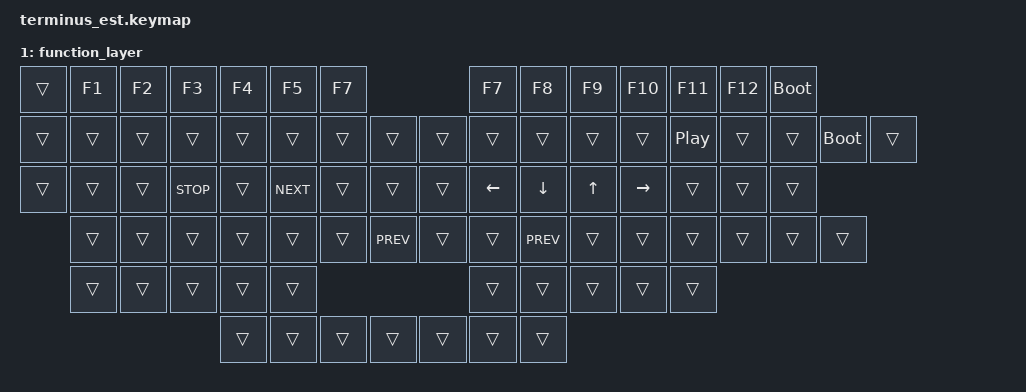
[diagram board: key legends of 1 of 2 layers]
/*
 * Copyright (c) 2024 The ZMK Contributors
 *
 * SPDX-License-Identifier: MIT
 */

#include <behaviors.dtsi>
#include <dt-bindings/zmk/keys.h>
#include <dt-bindings/zmk/bt.h>

/ {
    keymap {
        compatible = "zmk,keymap";

        default_layer {
// -----------------------------------------------------------------------------------------
// |  `  |  1  |  2  |  3  |  4  |  5  |  6  |                     |  7  |  8  |  9  |  0  |  -  |  +  | BKSP |
// | TAB | TAB |  Q  |  W  |  E  |  R  |  T  |  ESC |       | ESC |  Y  |  U  |  I  |  O  |  P  |  {  |  }  | BKSP |
// | CTRL| CTRL|  A  |  S  |  D  |  F  |  G  |  ALT |       | ALT |  H  |  J  |  K  |  L  |  ;  |  '  |  \  |
//       | SHFT| SHFT|  Z  |  X  |  C  |  V  |  B  |  CMD |       | CMD |  B  |  N  |  M  |  ,  |  .  |  /  | ENT |
//       | SHFT| SHFT|     | SPC | SPC | SPC |                     | SPC | SPC | SPC | ENT | ENT |
//                           | SPC | SPC | SPC |  FN  |       | SPC | SPC | SPC |
            bindings = <
   &kp GRAVE  &kp N1   &kp N2   &kp N3   &kp N4   &kp N5   &kp N6                         &kp N7   &kp N8    &kp N9    &kp N0   &kp MINUS &kp PLUS  &kp BSPC
   &kp TAB    &kp TAB  &kp Q    &kp W    &kp E    &kp R    &kp T    &kp ESC      &kp ESC   &kp Y    &kp U     &kp I     &kp O    &kp P     &kp LBRC  &kp RBRC  &kp BSPC
   &kp LCTRL  &kp LCTRL &kp A   &kp S    &kp D    &kp F    &kp G    &kp LALT     &kp LALT  &kp H    &kp J     &kp K     &kp L    &kp SEMI  &kp SQT   &kp BSLH
              &kp LSHFT &kp LSHFT &kp Z  &kp X    &kp C    &kp V    &kp B        &kp LGUI  &kp LGUI &kp B     &kp N     &kp M    &kp COMMA &kp DOT   &kp FSLH  &kp RET
              &kp LSHFT &kp LSHFT        &kp SPACE &kp SPACE &kp SPACE                     &kp SPACE &kp SPACE &kp SPACE &kp RET   &kp RET
                                         &kp SPACE &kp SPACE &kp SPACE &mo 1      &kp SPACE &kp SPACE &kp SPACE
            >;
        };

        function_layer {
// -----------------------------------------------------------------------------------------
// |     | F1  | F2  | F3  | F4  | F5  | F7  |                     | F7  | F8  | F9  | F10 | F11 | F12 | BOOT |
// |     |     |     |     |     |     |     |     |       |     |     |     |     |     | PLAY|     |     | BOOT |
// |     |     |     | STOP|     | NEXT|     |     |       |     | ← | ↓ | ↑ | → |     |     |     |
//       |     |     |     |     |     |     | PREV|     |       |     | PREV|     |     |     |     |     |     |
//       |     |     |     |     |     |     |                     |     |     |     |     |     |
//                           |     |     |     |     |       |     |     |     |
            bindings = <
   &trans     &kp F1   &kp F2   &kp F3   &kp F4   &kp F5   &kp F7                         &kp F7   &kp F8    &kp F9    &kp F10  &kp F11   &kp F12   &bootloader
   &trans     &trans   &trans   &trans   &trans   &trans   &trans   &trans      &trans    &trans   &trans    &trans    &trans   &kp C_PLAY_PAUSE &trans &trans &bootloader &trans
   &trans     &trans   &trans   &kp C_STOP &trans &kp C_NEXT &trans &trans      &trans    &kp LEFT &kp DOWN  &kp UP    &kp RIGHT &trans   &trans    &trans
              &trans   &trans   &trans   &trans   &trans   &trans   &kp C_PREV  &trans    &trans   &kp C_PREV &trans   &trans   &trans    &trans    &trans    &trans
              &trans   &trans            &trans   &trans   &trans                          &trans   &trans    &trans    &trans   &trans
                                         &trans   &trans   &trans   &trans      &trans    &trans   &trans
            >;
        };
    };
};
